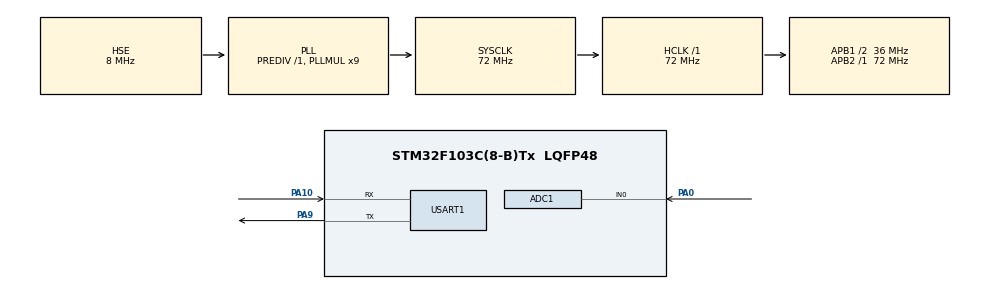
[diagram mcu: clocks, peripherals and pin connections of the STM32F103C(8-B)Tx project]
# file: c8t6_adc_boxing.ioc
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ADC1.Channel-0\#ChannelRegularConversion=ADC_CHANNEL_0
ADC1.DiscontinuousConvMode=DISABLE
ADC1.NbrOfConversion=1
ADC1.NbrOfConversionFlag=1
ADC1.Rank-0\#ChannelRegularConversion=1
ADC1.SamplingTime-0\#ChannelRegularConversion=ADC_SAMPLETIME_1CYCLE_5
ADC1.master=1
Mcu.Family=STM32F1
Mcu.Name=STM32F103C(8-B)Tx
Mcu.Package=LQFP48
NVIC.PriorityGroup=NVIC_PRIORITYGROUP_4
PA0-WKUP.Signal=ADCx_IN0
PA10.Mode=Asynchronous
PA10.Signal=USART1_RX
PA9.Mode=Asynchronous
PA9.Signal=USART1_TX
PD0-OSC_IN.Mode=HSE-External-Oscillator
PD0-OSC_IN.Signal=RCC_OSC_IN
PD1-OSC_OUT.Mode=HSE-External-Oscillator
PD1-OSC_OUT.Signal=RCC_OSC_OUT
ProjectManager.HeapSize=0x200
ProjectManager.StackSize=0x400
ProjectManager.TargetToolchain=MDK-ARM V5
RCC.ADCPresc=RCC_ADCPCLK2_DIV6
RCC.AHBFreq_Value=72000000
RCC.APB1CLKDivider=RCC_HCLK_DIV2
RCC.APB1Freq_Value=36000000
RCC.APB1TimFreq_Value=72000000
RCC.APB2Freq_Value=72000000
RCC.APB2TimFreq_Value=72000000
RCC.HCLKFreq_Value=72000000
RCC.PLLMUL=RCC_PLL_MUL9
RCC.PLLSourceVirtual=RCC_PLLSOURCE_HSE
RCC.SYSCLKFreq_VALUE=72000000
RCC.SYSCLKSource=RCC_SYSCLKSOURCE_PLLCLK
RCC.USBFreq_Value=72000000
SH.ADCx_IN0.0=ADC1_IN0,IN0
USART1.VirtualMode=VM_ASYNC
VP_SYS_VS_ND.Mode=No_Debug
board=custom

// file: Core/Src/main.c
/* USER CODE BEGIN Header */
/**
  ******************************************************************************
  * @file           : main.c
  * @brief          : Main program body
  ******************************************************************************
  * @attention
  *
  * <h2><center>&copy; Copyright (c) 2020 STMicroelectronics.
  * All rights reserved.</center></h2>
  *
  * This software component is licensed by ST under BSD 3-Clause license,
  * the "License"; You may not use this file except in compliance with the
  * License. You may obtain a copy of the License at:
  *                        opensource.org/licenses/BSD-3-Clause
  *
  ******************************************************************************
  */
/* USER CODE END Header */
#include "main.h"
#include "adc.h"
#include "usart.h"
#include "gpio.h"

/* USER CODE BEGIN Includes */
char filter_9(uint16_t value);
/* USER CODE END Includes */

void SystemClock_Config(void);

int main(void)
{
  /* USER CODE BEGIN 1 */
uint16_t i,j,m,n;
	float man;
  /* USER CODE END 1 */

  /* MCU Configuration--------------------------------------------------------*/

  /* Reset of all peripherals, Initializes the Flash interface and the Systick. */
  HAL_Init();

  /* Configure the system clock */
  SystemClock_Config();

  /* Initialize all configured peripherals */
  MX_GPIO_Init();
  MX_ADC1_Init();
  MX_USART1_UART_Init();

  /* Infinite loop */
  /* USER CODE BEGIN WHILE */
  while (1)
  {
//		    HAL_ADC_Start(&hadc1);                    //启动ADC单次转换
//        HAL_ADC_PollForConversion(&hadc1, 50);    //等待ADC转换完成
//        smoke_value = HAL_ADC_GetValue(&hadc1); //读取ADC转换数据
//        printf("$,%d", smoke_value);

		 i=get_ad();//正常采集
		 m=filter2();//中位值滤波算法
		 man=(float)i;
		 man=KalmanFilter(man);//卡尔曼滤波
		 printf("$,%d,%d,%f",i,m,man);
     HAL_Delay(10);
    /* USER CODE END WHILE */

  }
}

void SystemClock_Config(void)
{
  RCC_OscInitTypeDef RCC_OscInitStruct = {0};
  RCC_ClkInitTypeDef RCC_ClkInitStruct = {0};
  RCC_PeriphCLKInitTypeDef PeriphClkInit = {0};

  /** Initializes the RCC Oscillators according to the specified parameters
  * in the RCC_OscInitTypeDef structure.
  */
  RCC_OscInitStruct.OscillatorType = RCC_OSCILLATORTYPE_HSE;
  RCC_OscInitStruct.HSEState = RCC_HSE_ON;
  RCC_OscInitStruct.HSEPredivValue = RCC_HSE_PREDIV_DIV1;
  RCC_OscInitStruct.HSIState = RCC_HSI_ON;
  RCC_OscInitStruct.PLL.PLLState = RCC_PLL_ON;
  RCC_OscInitStruct.PLL.PLLSource = RCC_PLLSOURCE_HSE;
  RCC_OscInitStruct.PLL.PLLMUL = RCC_PLL_MUL9;
  if (HAL_RCC_OscConfig(&RCC_OscInitStruct) != HAL_OK)
  {
    Error_Handler();
  }
  /** Initializes the CPU, AHB and APB buses clocks
  */
  RCC_ClkInitStruct.ClockType = RCC_CLOCKTYPE_HCLK|RCC_CLOCKTYPE_SYSCLK
                              |RCC_CLOCKTYPE_PCLK1|RCC_CLOCKTYPE_PCLK2;
  RCC_ClkInitStruct.SYSCLKSource = RCC_SYSCLKSOURCE_PLLCLK;
  RCC_ClkInitStruct.AHBCLKDivider = RCC_SYSCLK_DIV1;
  RCC_ClkInitStruct.APB1CLKDivider = RCC_HCLK_DIV2;
  RCC_ClkInitStruct.APB2CLKDivider = RCC_HCLK_DIV1;

  if (HAL_RCC_ClockConfig(&RCC_ClkInitStruct, FLASH_LATENCY_2) != HAL_OK)
  {
    Error_Handler();
  }
  PeriphClkInit.PeriphClockSelection = RCC_PERIPHCLK_ADC;
  PeriphClkInit.AdcClockSelection = RCC_ADCPCLK2_DIV6;
  if (HAL_RCCEx_PeriphCLKConfig(&PeriphClkInit) != HAL_OK)
  {
    Error_Handler();
  }
}

/* USER CODE BEGIN 4 */
/**消抖滤波法**/
#undef N
#define N 2 //设置计数器溢出值
char filter_9(uint16_t value)
{
   char count=0; //计数变量
   char new_value; //本次采样值变量
   new_value = get_ad(); //读入本次采样值
   while (value !=new_value)
   {
      count++; //计数器加1
      if (count>=N)   return new_value; //如果本次采样值与当前有效值不相等，
//且计数器溢出，返回本次采样值
       HAL_Delay (1);
      new_value = get_ad();
   }
   return value; //如果本次采样值与当前有效值相等，则返回当前有效值
}
/* USER CODE END 4 */

void Error_Handler(void)
{
}

/************************ (C) COPYRIGHT STMicroelectronics *****END OF FILE****/
